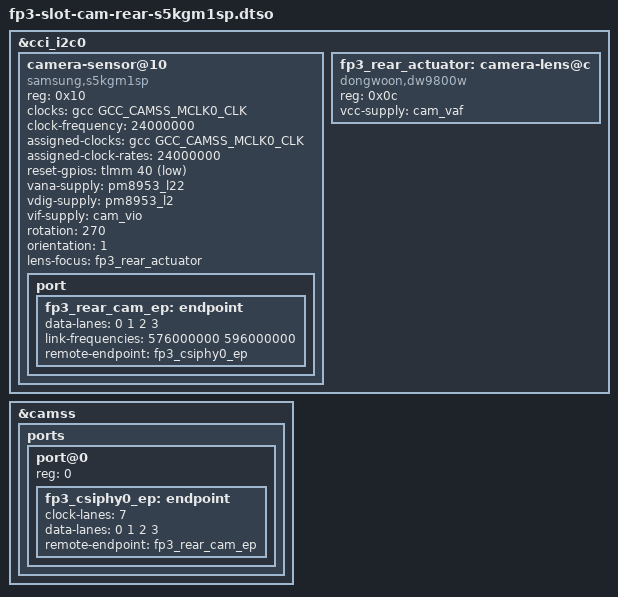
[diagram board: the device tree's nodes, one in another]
// SPDX-License-Identifier: BSD-3-Clause
/*
 * Fairphone 3+ rear camera module: Samsung S5KGM1SP (48MP) behind a
 * Dongwoon DW9800W voice coil motor, on CSIPHY0.
 *
 * Applied by drivers/misc/fp3_module_slot.c when the rear slot answers
 * at 0x10 with model ID 0x08d1.
 */
/dts-v1/;
/plugin/;

#include <dt-bindings/clock/qcom,gcc-msm8953.h>
#include <dt-bindings/gpio/gpio.h>

&cci_i2c0 {
	#address-cells = <1>;
	#size-cells = <0>;

	camera-sensor@10 {
		compatible = "samsung,s5kgm1sp";
		reg = <0x10>;

		clocks = <&gcc GCC_CAMSS_MCLK0_CLK>;
		clock-frequency = <24000000>;
		assigned-clocks = <&gcc GCC_CAMSS_MCLK0_CLK>;
		assigned-clock-rates = <24000000>;

		reset-gpios = <&tlmm 40 GPIO_ACTIVE_LOW>;

		vana-supply = <&pm8953_l22>;
		vdig-supply = <&pm8953_l2>;
		vif-supply = <&cam_vio>;

		rotation = <270>;
		orientation = <1>;

		lens-focus = <&fp3_rear_actuator>;

		port {
			fp3_rear_cam_ep: endpoint {
				data-lanes = <0 1 2 3>;
				link-frequencies = /bits/ 64 <576000000 596000000>;
				remote-endpoint = <&fp3_csiphy0_ep>;
			};
		};
	};

	/*
	 * Register-addressed I2C protocol, position in register 0x03 —
	 * not the AK7374 the Fairphone 3 uses.
	 */
	fp3_rear_actuator: camera-lens@c {
		compatible = "dongwoon,dw9800w";
		reg = <0x0c>;

		vcc-supply = <&cam_vaf>;
	};
};

&camss {
	ports {
		#address-cells = <1>;
		#size-cells = <0>;

		port@0 {
			reg = <0>;

			fp3_csiphy0_ep: endpoint {
				clock-lanes = <7>;
				data-lanes = <0 1 2 3>;
				remote-endpoint = <&fp3_rear_cam_ep>;
			};
		};
	};
};
